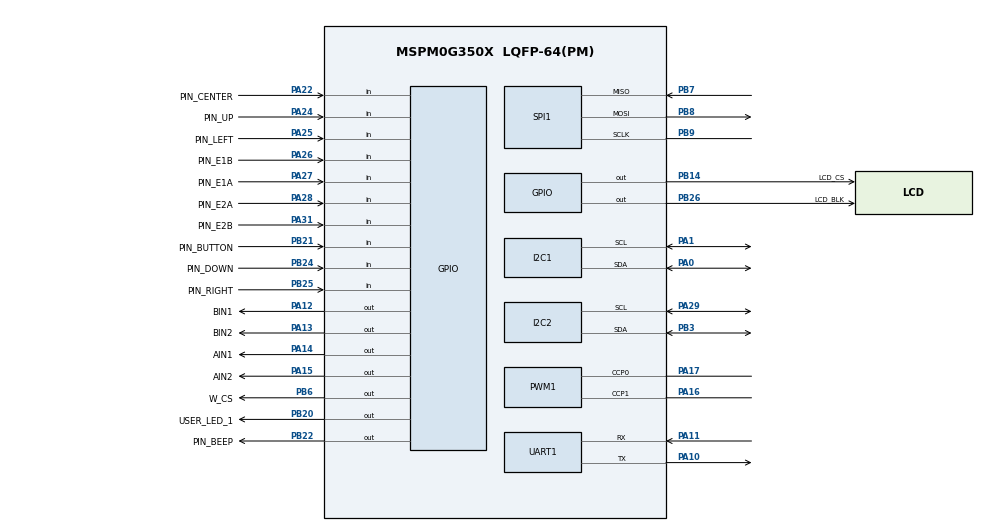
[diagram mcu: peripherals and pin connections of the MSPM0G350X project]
/**
 * @cliArgs --device "MSPM0G350X" --part "Default" --package "LQFP-64(PM)" --product "mspm0_sdk@2.10.00.04"
 * @versions {"tool":"1.27.0+4565"}
 */

/**
 * Import the modules used in this configuration.
 */
const DMA           = scripting.addModule("/ti/driverlib/DMA");
const GPIO          = scripting.addModule("/ti/driverlib/GPIO", {}, false);
const GPIO1         = GPIO.addInstance();
const GPIO2         = GPIO.addInstance();
const GPIO3         = GPIO.addInstance();
const GPIO4         = GPIO.addInstance();
const GPIO5         = GPIO.addInstance();
const GPIO6         = GPIO.addInstance();
const GPIO7         = GPIO.addInstance();
const I2C           = scripting.addModule("/ti/driverlib/I2C", {}, false);
const I2C1          = I2C.addInstance();
const I2C2          = I2C.addInstance();
const PWM           = scripting.addModule("/ti/driverlib/PWM", {}, false);
const PWM1          = PWM.addInstance();
const SPI           = scripting.addModule("/ti/driverlib/SPI", {}, false);
const SPI1          = SPI.addInstance();
const SYSCTL        = scripting.addModule("/ti/driverlib/SYSCTL");
const TIMER         = scripting.addModule("/ti/driverlib/TIMER", {}, false);
const TIMER1        = TIMER.addInstance();
const UART          = scripting.addModule("/ti/driverlib/UART", {}, false);
const UART1         = UART.addInstance();
const ProjectConfig = scripting.addModule("/ti/project_config/ProjectConfig");

/**
 * Write custom configuration values to the imported modules.
 */
const divider6       = system.clockTree["PLL_CLK2X_DIV"];
divider6.divideValue = 4;

const divider7       = system.clockTree["PLL_PDIV"];
divider7.divideValue = 2;

const divider9       = system.clockTree["UDIV"];
divider9.divideValue = 2;

const multiplier2         = system.clockTree["PLL_QDIV"];
multiplier2.multiplyValue = 10;

const mux8       = system.clockTree["HSCLKMUX"];
mux8.inputSelect = "HSCLKMUX_SYSPLL2X";

const pinFunction4     = system.clockTree["HFXT"];
pinFunction4.inputFreq = 40;
pinFunction4.enable    = true;

const Board = scripting.addModule("/ti/driverlib/Board", {}, false);

GPIO1.$name                          = "GPIO_LEDS";
GPIO1.associatedPins[0].$name        = "USER_LED_1";
GPIO1.associatedPins[0].assignedPort = "PORTB";
GPIO1.associatedPins[0].assignedPin  = "20";
GPIO1.associatedPins[0].pin.$assign  = "PB20";

GPIO2.$name                              = "GPIO_KEY";
GPIO2.associatedPins.create(6);
GPIO2.associatedPins[0].$name            = "PIN_UP";
GPIO2.associatedPins[0].direction        = "INPUT";
GPIO2.associatedPins[0].internalResistor = "PULL_UP";
GPIO2.associatedPins[0].assignedPort     = "PORTA";
GPIO2.associatedPins[0].assignedPin      = "24";
GPIO2.associatedPins[0].pin.$assign      = "PA24";
GPIO2.associatedPins[1].$name            = "PIN_LEFT";
GPIO2.associatedPins[1].direction        = "INPUT";
GPIO2.associatedPins[1].internalResistor = "PULL_UP";
GPIO2.associatedPins[1].assignedPort     = "PORTA";
GPIO2.associatedPins[1].assignedPin      = "25";
GPIO2.associatedPins[1].pin.$assign      = "PA25";
GPIO2.associatedPins[2].$name            = "PIN_DOWN";
GPIO2.associatedPins[2].direction        = "INPUT";
GPIO2.associatedPins[2].internalResistor = "PULL_UP";
GPIO2.associatedPins[2].assignedPort     = "PORTB";
GPIO2.associatedPins[2].assignedPin      = "24";
GPIO2.associatedPins[2].pin.$assign      = "PB24";
GPIO2.associatedPins[3].$name            = "PIN_RIGHT";
GPIO2.associatedPins[3].direction        = "INPUT";
GPIO2.associatedPins[3].internalResistor = "PULL_UP";
GPIO2.associatedPins[3].assignedPort     = "PORTB";
GPIO2.associatedPins[3].assignedPin      = "25";
GPIO2.associatedPins[3].pin.$assign      = "PB25";
GPIO2.associatedPins[4].$name            = "PIN_CENTER";
GPIO2.associatedPins[4].direction        = "INPUT";
GPIO2.associatedPins[4].assignedPort     = "PORTA";
GPIO2.associatedPins[4].assignedPin      = "22";
GPIO2.associatedPins[4].internalResistor = "PULL_UP";
GPIO2.associatedPins[4].pin.$assign      = "PA22";
GPIO2.associatedPins[5].$name            = "PIN_BUTTON";
GPIO2.associatedPins[5].direction        = "INPUT";
GPIO2.associatedPins[5].internalResistor = "PULL_UP";
GPIO2.associatedPins[5].assignedPort     = "PORTB";
GPIO2.associatedPins[5].assignedPin      = "21";
GPIO2.associatedPins[5].pin.$assign      = "PB21";

GPIO3.$name                          = "GPIO_LCD";
GPIO3.associatedPins.create(4);
GPIO3.associatedPins[0].assignedPort = "PORTB";
GPIO3.associatedPins[0].assignedPin  = "10";
GPIO3.associatedPins[0].$name        = "LCD_RES";
GPIO3.associatedPins[1].assignedPort = "PORTB";
GPIO3.associatedPins[1].assignedPin  = "11";
GPIO3.associatedPins[1].$name        = "LCD_DC";
GPIO3.associatedPins[1].initialValue = "SET";
GPIO3.associatedPins[2].$name        = "LCD_CS";
GPIO3.associatedPins[2].assignedPort = "PORTB";
GPIO3.associatedPins[2].assignedPin  = "14";
GPIO3.associatedPins[2].initialValue = "SET";
GPIO3.associatedPins[2].pin.$assign  = "PB14";
GPIO3.associatedPins[3].$name        = "LCD_BLK";
GPIO3.associatedPins[3].assignedPort = "PORTB";
GPIO3.associatedPins[3].assignedPin  = "26";
GPIO3.associatedPins[3].pin.$assign  = "PB26";

GPIO4.$name                          = "GPIO_W25Q";
GPIO4.associatedPins[0].$name        = "W_CS";
GPIO4.associatedPins[0].ioStructure  = "SD";
GPIO4.associatedPins[0].assignedPort = "PORTB";
GPIO4.associatedPins[0].assignedPin  = "6";
GPIO4.associatedPins[0].initialValue = "SET";
GPIO4.associatedPins[0].pin.$assign  = "PB6";

GPIO5.$name                         = "GPIO_MOTOR";
GPIO5.associatedPins.create(4);
GPIO5.associatedPins[0].$name       = "BIN1";
GPIO5.associatedPins[0].pin.$assign = "PA12";
GPIO5.associatedPins[1].$name       = "BIN2";
GPIO5.associatedPins[1].pin.$assign = "PA13";
GPIO5.associatedPins[2].$name       = "AIN1";
GPIO5.associatedPins[2].pin.$assign = "PA14";
GPIO5.associatedPins[3].$name       = "AIN2";
GPIO5.associatedPins[3].pin.$assign = "PA15";

GPIO6.$name                               = "GPIO_ENC";
GPIO6.associatedPins.create(4);
GPIO6.associatedPins[0].$name             = "PIN_E1A";
GPIO6.associatedPins[0].direction         = "INPUT";
GPIO6.associatedPins[0].interruptEn       = true;
GPIO6.associatedPins[0].polarity          = "RISE";
GPIO6.associatedPins[0].interruptPriority = "2";
GPIO6.associatedPins[0].pin.$assign       = "PA27";
GPIO6.associatedPins[1].$name             = "PIN_E1B";
GPIO6.associatedPins[1].direction         = "INPUT";
GPIO6.associatedPins[1].interruptEn       = true;
GPIO6.associatedPins[1].polarity          = "RISE";
GPIO6.associatedPins[1].interruptPriority = "2";
GPIO6.associatedPins[1].pin.$assign       = "PA26";
GPIO6.associatedPins[2].$name             = "PIN_E2A";
GPIO6.associatedPins[2].direction         = "INPUT";
GPIO6.associatedPins[2].interruptEn       = true;
GPIO6.associatedPins[2].polarity          = "RISE";
GPIO6.associatedPins[2].interruptPriority = "2";
GPIO6.associatedPins[2].pin.$assign       = "PA28";
GPIO6.associatedPins[3].$name             = "PIN_E2B";
GPIO6.associatedPins[3].direction         = "INPUT";
GPIO6.associatedPins[3].interruptEn       = true;
GPIO6.associatedPins[3].polarity          = "RISE";
GPIO6.associatedPins[3].interruptPriority = "2";
GPIO6.associatedPins[3].pin.$assign       = "PA31";

GPIO7.$name                         = "GPIO_BEEP";
GPIO7.associatedPins[0].$name       = "PIN_BEEP";
GPIO7.associatedPins[0].pin.$assign = "PB22";

I2C1.$name                           = "I2C_0";
I2C1.basicEnableController           = true;
I2C1.basicControllerStandardBusSpeed = "FastPlus";
I2C1.DMAEvent1                       = "CONTROLLER_TXFIFO_TRIGGER";
I2C1.DMAEvent2                       = "CONTROLLER_RXFIFO_TRIGGER";
I2C1.peripheral.sdaPin.$assign       = "PA0";
I2C1.peripheral.sclPin.$assign       = "PA1";
I2C1.sdaPinConfig.$name              = "ti_driverlib_gpio_GPIOPinGeneric2";
I2C1.sclPinConfig.$name              = "ti_driverlib_gpio_GPIOPinGeneric3";
I2C1.DMA_CHANNEL_EVENT1.$name        = "DMA_I2C_TX";
I2C1.DMA_CHANNEL_EVENT1.srcLength    = "BYTE";
I2C1.DMA_CHANNEL_EVENT1.dstLength    = "BYTE";
I2C1.DMA_CHANNEL_EVENT1.addressMode  = "b2f";
I2C1.DMA_CHANNEL_EVENT2.$name        = "DMA_I2C_RX";
I2C1.DMA_CHANNEL_EVENT2.srcLength    = "BYTE";
I2C1.DMA_CHANNEL_EVENT2.dstLength    = "BYTE";
I2C1.DMA_CHANNEL_EVENT2.addressMode  = "f2b";

I2C2.$name                             = "I2C_NCHD12";
I2C2.basicEnableController             = true;
I2C2.DMAEvent2                         = "CONTROLLER_RXFIFO_TRIGGER";
I2C2.peripheral.sdaPin.$assign         = "PB3";
I2C2.peripheral.sclPin.$assign         = "PA29";
I2C2.sdaPinConfig.hideOutputInversion  = scripting.forceWrite(false);
I2C2.sdaPinConfig.onlyInternalResistor = scripting.forceWrite(false);
I2C2.sdaPinConfig.passedPeripheralType = scripting.forceWrite("Digital");
I2C2.sdaPinConfig.$name                = "ti_driverlib_gpio_GPIOPinGeneric7";
I2C2.sclPinConfig.hideOutputInversion  = scripting.forceWrite(false);
I2C2.sclPinConfig.onlyInternalResistor = scripting.forceWrite(false);
I2C2.sclPinConfig.passedPeripheralType = scripting.forceWrite("Digital");
I2C2.sclPinConfig.$name                = "ti_driverlib_gpio_GPIOPinGeneric8";
I2C2.DMA_CHANNEL_EVENT2.$name          = "DMA_CH0";
I2C2.DMA_CHANNEL_EVENT2.addressMode    = "f2b";
I2C2.DMA_CHANNEL_EVENT2.srcLength      = "BYTE";
I2C2.DMA_CHANNEL_EVENT2.dstLength      = "BYTE";

PWM1.$name                              = "PWM_MOTOR";
PWM1.peripheral.$assign                 = "TIMA1";
PWM1.peripheral.ccp0Pin.$assign         = "PA17";
PWM1.peripheral.ccp1Pin.$assign         = "PA16";
PWM1.PWM_CHANNEL_0.$name                = "ti_driverlib_pwm_PWMTimerCC0";
PWM1.PWM_CHANNEL_0.invert               = true;
PWM1.PWM_CHANNEL_1.$name                = "ti_driverlib_pwm_PWMTimerCC1";
PWM1.PWM_CHANNEL_1.invert               = true;
PWM1.ccp0PinConfig.direction            = scripting.forceWrite("OUTPUT");
PWM1.ccp0PinConfig.hideOutputInversion  = scripting.forceWrite(false);
PWM1.ccp0PinConfig.onlyInternalResistor = scripting.forceWrite(false);
PWM1.ccp0PinConfig.passedPeripheralType = scripting.forceWrite("Digital");
PWM1.ccp0PinConfig.$name                = "ti_driverlib_gpio_GPIOPinGeneric9";
PWM1.ccp1PinConfig.direction            = scripting.forceWrite("OUTPUT");
PWM1.ccp1PinConfig.hideOutputInversion  = scripting.forceWrite(false);
PWM1.ccp1PinConfig.onlyInternalResistor = scripting.forceWrite(false);
PWM1.ccp1PinConfig.passedPeripheralType = scripting.forceWrite("Digital");
PWM1.ccp1PinConfig.$name                = "ti_driverlib_gpio_GPIOPinGeneric10";

SPI1.$name                              = "SPI_LCD";
SPI1.frameFormat                        = "MOTO3";
SPI1.enabledDMAEvent2Triggers           = "DL_SPI_DMA_INTERRUPT_TX";
SPI1.enabledDMAEvent1Triggers           = "DL_SPI_DMA_INTERRUPT_RX";
SPI1.targetBitRate                      = 20000000;
SPI1.sclkPinConfig.direction            = scripting.forceWrite("OUTPUT");
SPI1.sclkPinConfig.onlyInternalResistor = scripting.forceWrite(false);
SPI1.sclkPinConfig.passedPeripheralType = scripting.forceWrite("Digital");
SPI1.sclkPinConfig.$name                = "ti_driverlib_gpio_GPIOPinGeneric4";
SPI1.mosiPinConfig.direction            = scripting.forceWrite("OUTPUT");
SPI1.mosiPinConfig.hideOutputInversion  = scripting.forceWrite(false);
SPI1.mosiPinConfig.onlyInternalResistor = scripting.forceWrite(false);
SPI1.mosiPinConfig.passedPeripheralType = scripting.forceWrite("Digital");
SPI1.mosiPinConfig.$name                = "ti_driverlib_gpio_GPIOPinGeneric5";
SPI1.misoPinConfig.onlyInternalResistor = scripting.forceWrite(false);
SPI1.misoPinConfig.passedPeripheralType = scripting.forceWrite("Digital");
SPI1.misoPinConfig.$name                = "ti_driverlib_gpio_GPIOPinGeneric6";
SPI1.peripheral.sclkPin.$assign         = "PB9";
SPI1.peripheral.mosiPin.$assign         = "PB8";
SPI1.peripheral.misoPin.$assign         = "PB7";
SPI1.DMA_CHANNEL_EVENT2.$name           = "DMA_SPI_LCD_TX";
SPI1.DMA_CHANNEL_EVENT2.addressMode     = "b2f";
SPI1.DMA_CHANNEL_EVENT2.srcLength       = "BYTE";
SPI1.DMA_CHANNEL_EVENT2.dstLength       = "BYTE";
SPI1.DMA_CHANNEL_EVENT1.addressMode     = "f2b";
SPI1.DMA_CHANNEL_EVENT1.srcLength       = "BYTE";
SPI1.DMA_CHANNEL_EVENT1.dstLength       = "BYTE";
SPI1.DMA_CHANNEL_EVENT1.$name           = "DMA_SPI_LCD_RX";

SYSCTL.clockTreeEn = true;

TIMER1.timerClkDiv       = 8;
TIMER1.timerClkPrescale  = 10;
TIMER1.timerPeriod       = "10 ms";
TIMER1.$name             = "TIMER_10ms";
TIMER1.timerMode         = "PERIODIC";
TIMER1.interruptPriority = "1";
TIMER1.interrupts        = ["ZERO"];

UART1.$name                      = "UART_0";
UART1.targetBaudRate             = 115200;
UART1.interruptPriority          = "3";
UART1.enabledDMARXTriggers       = "DL_UART_DMA_INTERRUPT_RX";
UART1.enabledDMATXTriggers       = "DL_UART_DMA_INTERRUPT_TX";
UART1.peripheral.rxPin.$assign   = "PA11";
UART1.peripheral.txPin.$assign   = "PA10";
UART1.txPinConfig.$name          = "ti_driverlib_gpio_GPIOPinGeneric0";
UART1.rxPinConfig.$name          = "ti_driverlib_gpio_GPIOPinGeneric1";
UART1.DMA_CHANNEL_RX.srcLength   = "BYTE";
UART1.DMA_CHANNEL_RX.dstLength   = "BYTE";
UART1.DMA_CHANNEL_RX.$name       = "DMA_UART_RX";
UART1.DMA_CHANNEL_RX.addressMode = "f2b";
UART1.DMA_CHANNEL_TX.srcLength   = "BYTE";
UART1.DMA_CHANNEL_TX.dstLength   = "BYTE";
UART1.DMA_CHANNEL_TX.$name       = "DMA_UART_TX";
UART1.DMA_CHANNEL_TX.addressMode = "b2f";

ProjectConfig.genDisable = true;
scripting.suppress("Project Configuration File generation is disabled for this project\\. SysConfig Project Migration is not currently supported for this project\\.", ProjectConfig);

/**
 * Pinmux solution for unlocked pins/peripherals. This ensures that minor changes to the automatic solver in a future
 * version of the tool will not impact the pinmux you originally saw.  These lines can be completely deleted in order to
 * re-solve from scratch.
 */
pinFunction4.peripheral.$suggestSolution            = "SYSCTL";
pinFunction4.peripheral.hfxInPin.$suggestSolution   = "PA5";
pinFunction4.peripheral.hfxOutPin.$suggestSolution  = "PA6";
Board.peripheral.$suggestSolution                   = "DEBUGSS";
Board.peripheral.swclkPin.$suggestSolution          = "PA20";
Board.peripheral.swdioPin.$suggestSolution          = "PA19";
GPIO3.associatedPins[0].pin.$suggestSolution        = "PB10";
GPIO3.associatedPins[1].pin.$suggestSolution        = "PB11";
I2C1.peripheral.$suggestSolution                    = "I2C0";
I2C1.DMA_CHANNEL_EVENT1.peripheral.$suggestSolution = "DMA_CH6";
I2C1.DMA_CHANNEL_EVENT2.peripheral.$suggestSolution = "DMA_CH5";
I2C2.peripheral.$suggestSolution                    = "I2C1";
I2C2.DMA_CHANNEL_EVENT2.peripheral.$suggestSolution = "DMA_CH4";
SPI1.peripheral.$suggestSolution                    = "SPI1";
SPI1.DMA_CHANNEL_EVENT2.peripheral.$suggestSolution = "DMA_CH3";
SPI1.DMA_CHANNEL_EVENT1.peripheral.$suggestSolution = "DMA_CH2";
TIMER1.peripheral.$suggestSolution                  = "TIMA0";
UART1.peripheral.$suggestSolution                   = "UART0";
UART1.DMA_CHANNEL_RX.peripheral.$suggestSolution    = "DMA_CH1";
UART1.DMA_CHANNEL_TX.peripheral.$suggestSolution    = "DMA_CH0";
